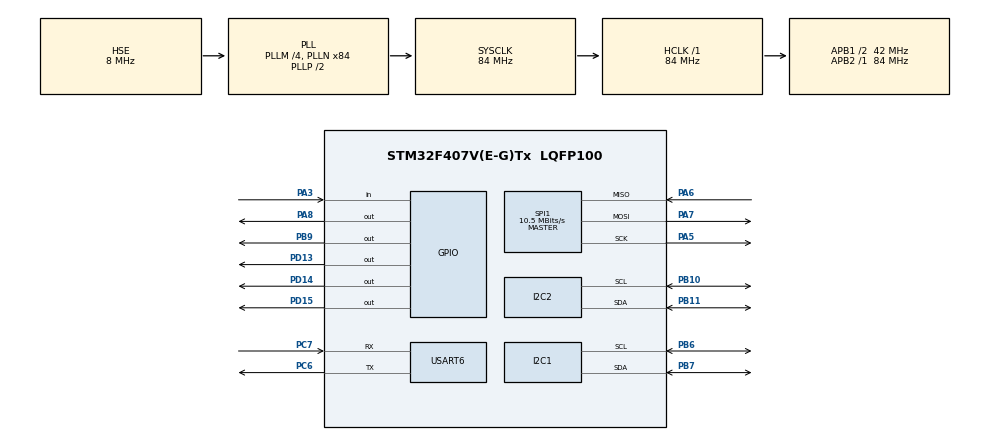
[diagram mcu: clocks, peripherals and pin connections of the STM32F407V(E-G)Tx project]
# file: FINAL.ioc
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Mcu.Family=STM32F4
Mcu.Name=STM32F407V(E-G)Tx
Mcu.Package=LQFP100
NVIC.PriorityGroup=NVIC_PRIORITYGROUP_0
PA13.Mode=Serial_Wire
PA13.Signal=SYS_JTMS-SWDIO
PA14.Mode=Serial_Wire
PA14.Signal=SYS_JTCK-SWCLK
PA3.Signal=GPIO_Input
PA5.Mode=Full_Duplex_Master
PA5.Signal=SPI1_SCK
PA6.Mode=Full_Duplex_Master
PA6.Signal=SPI1_MISO
PA7.Mode=Full_Duplex_Master
PA7.Signal=SPI1_MOSI
PA8.Signal=GPIO_Output
PB10.Mode=I2C
PB10.Signal=I2C2_SCL
PB11.Mode=I2C
PB11.Signal=I2C2_SDA
PB6.Mode=I2C
PB6.Signal=I2C1_SCL
PB7.Mode=I2C
PB7.Signal=I2C1_SDA
PB9.Signal=GPIO_Output
PC6.Mode=Asynchronous
PC6.Signal=USART6_TX
PC7.Mode=Asynchronous
PC7.Signal=USART6_RX
PD13.Signal=GPIO_Output
PD14.Signal=GPIO_Output
PD15.Signal=GPIO_Output
PH0-OSC_IN.Mode=HSE-External-Oscillator
PH0-OSC_IN.Signal=RCC_OSC_IN
PH1-OSC_OUT.Mode=HSE-External-Oscillator
PH1-OSC_OUT.Signal=RCC_OSC_OUT
ProjectManager.HeapSize=0x200
ProjectManager.StackSize=0x400
ProjectManager.TargetToolchain=MDK-ARM V5.32
RCC.48MHZClocksFreq_Value=24000000
RCC.AHBFreq_Value=84000000
RCC.APB1CLKDivider=RCC_HCLK_DIV2
RCC.APB1Freq_Value=42000000
RCC.APB1TimFreq_Value=84000000
RCC.APB2Freq_Value=84000000
RCC.APB2TimFreq_Value=84000000
RCC.CortexFreq_Value=84000000
RCC.HCLKFreq_Value=84000000
RCC.HSE_VALUE=8000000
RCC.HSI_VALUE=16000000
RCC.LSE_VALUE=32768
RCC.PLLM=4
RCC.PLLN=84
RCC.PLLQ=7
RCC.PLLSourceVirtual=RCC_PLLSOURCE_HSE
RCC.SYSCLKFreq_VALUE=84000000
RCC.SYSCLKSource=RCC_SYSCLKSOURCE_PLLCLK
RCC.VCOOutputFreq_Value=168000000
SPI1.BaudRatePrescaler=SPI_BAUDRATEPRESCALER_8
SPI1.CalculateBaudRate=10.5 MBits/s
SPI1.Direction=SPI_DIRECTION_2LINES
SPI1.Mode=SPI_MODE_MASTER
SPI1.VirtualType=VM_MASTER
USART6.VirtualMode=VM_ASYNC
board=STM32F407G-DISC1

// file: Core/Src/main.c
/* USER CODE BEGIN Header */
/**
  ******************************************************************************
  * @file           : main.c
  * @brief          : Main program body
  ******************************************************************************
  * @attention
  *
  * Copyright (c) 2025 STMicroelectronics.
  * All rights reserved.
  *
  * This software is licensed under terms that can be found in the LICENSE file
  * in the root directory of this software component.
  * If no LICENSE file comes with this software, it is provided AS-IS.
  *
  ******************************************************************************
  */
/* USER CODE END Header */
#include "main.h"
#include "RC522.h"
#include "string.h"
#include "TJ_MPU6050.h"
#include "liquidcrystal_i2c.h"
uint8_t i;
#define HIGH_BYTE(x) ((x >> 12) & 0xFF)

I2C_HandleTypeDef hi2c1;
I2C_HandleTypeDef hi2c2;

SPI_HandleTypeDef hspi1;

UART_HandleTypeDef huart6;

void SystemClock_Config(void);
static void MX_GPIO_Init(void);
static void MX_I2C1_Init(void);
static void MX_I2C2_Init(void);
static void MX_SPI1_Init(void);
static void MX_USART6_UART_Init(void);
uint8_t status;
uint8_t str[16];
uint8_t sNum[5];
RawData_Def rawaccelo, rawgyro;
ScaledData_Def scaledaccelo, scaledgyro;
ScaledData_Def previacc,previgyro;
RawData_Def prevacc,prevgyro;

int main(void)
	{
MPU_ConfigTypeDef myconfig;

  /* MCU Configuration--------------------------------------------------------*/

  /* Reset of all peripherals, Initializes the Flash interface and the Systick. */
  HAL_Init();

  /* Configure the system clock */
  SystemClock_Config();

  /* Initialize all configured peripherals */
  MX_GPIO_Init();
  MX_I2C1_Init();
  MX_I2C2_Init();
  MX_SPI1_Init();
  MX_USART6_UART_Init();
	MFRC522_Init();
	MPU6050_Init(&hi2c2);
	myconfig.Accel_Full_Scale=AFS_SEL_4g;
	myconfig.ClockSource=Internal_8MHz;
	myconfig.CONFIG_DLPF=DLPF_184A_188G_Hz;
	myconfig.Gyro_Full_Scale=FS_SEL_500;
	myconfig.Sleep_Mode_Bit=0;
	MPU6050_Config(&myconfig);
	HD44780_Backlight();
 HD44780_Init(2);
  HD44780_Clear();
	previacc = (ScaledData_Def){0};
	prevacc = (RawData_Def){0};
uint8_t tag_found = 0;

  /* Infinite loop */
  /* USER CODE BEGIN WHILE */
  while (1)
  {HD44780_Clear();
    /* USER CODE END WHILE */
		MPU6050_Get_Accel_RawData(&rawaccelo);
		MPU6050_Get_Accel_Scale(&scaledaccelo);

		if (HIGH_BYTE(rawaccelo.x) != HIGH_BYTE(prevacc.x) ||
    HIGH_BYTE(rawaccelo.y) != HIGH_BYTE(prevacc.y) ||
    HIGH_BYTE(rawaccelo.z) != HIGH_BYTE(prevacc.z)) {
    // Movement detected
		HAL_GPIO_WritePin(GPIOD,GPIO_PIN_14,GPIO_PIN_SET);
		HAL_UART_Transmit(&huart6, (uint8_t*)"The thing is moved", strlen("The thing is moved "), 1000);
		HAL_Delay(100);
		HD44780_SetCursor(0,1);
			HD44780_PrintStr("Danger");
		HAL_Delay(1000);

}

		else
		{
			HD44780_SetCursor(0, 1);
HD44780_PrintStr("                ");
			HAL_GPIO_WritePin(GPIOD,GPIO_PIN_14,GPIO_PIN_RESET);

		}
		prevacc=rawaccelo;

		if(HAL_GPIO_ReadPin(GPIOA,GPIO_PIN_3)==GPIO_PIN_RESET){
			HAL_GPIO_WritePin(GPIOD,GPIO_PIN_13,GPIO_PIN_SET);
			HAL_UART_Transmit(&huart6, (uint8_t*)"Entry detected", strlen("Entry detected"), 1000);
			HAL_Delay(100);
			HD44780_Clear();
			HD44780_SetCursor(0,0);
			 HD44780_PrintStr("Entry Detected");
			HD44780_SetCursor(0,1);
			HD44780_PrintStr("Scan Card");
			 HD44780_Display();
			HAL_Delay(1000);
			tag_found = 0;
memset(sNum, 0, sizeof(sNum));
			i=0;
			while(i<25){
		status=MFRC522_Request(PICC_REQIDL,str);
		status=MFRC522_Anticoll(str);

		HAL_Delay(200);
				i++;
				if (status == MI_OK) {
            memcpy(sNum, str, 5);
            tag_found = 1;
            break;  // Exit early on success
        }
			}
			if(sNum[2]==0x20){
				HD44780_Clear();
				HD44780_SetCursor(0,0);
				HD44780_PrintStr("Authorized");
				 HD44780_Display();
				HAL_Delay(100);
				HAL_UART_Transmit(&huart6, (uint8_t*)"Authorizedaccess", strlen("Authorizedaccess"), 1000);
				HAL_Delay(3000);
				sNum[2]=0x00;
			}
			else if(sNum[2]==0xC8){
				HAL_UART_Transmit(&huart6, (uint8_t*)"Unauthorized access", strlen("Unauthorized access"), 1000);
				HAL_GPIO_WritePin(GPIOD,GPIO_PIN_15,GPIO_PIN_SET);
				HAL_Delay(100);
				HD44780_Clear();
				HD44780_SetCursor(0,0);
				HD44780_PrintStr("unauthorized");
			 HD44780_Display();
				HAL_Delay(3000);
				sNum[2]=0x00;
				HAL_GPIO_WritePin(GPIOD,GPIO_PIN_15,GPIO_PIN_RESET);
			}
			else if(sNum[2]==0x25){
				HD44780_Clear();
				HD44780_SetCursor(0,0);
				HD44780_PrintStr("Authorized");
				HD44780_Display();
				HAL_Delay(100);
				HAL_UART_Transmit(&huart6, (uint8_t*)"Authorizedaccess", strlen("Authorizedaccess"), 1000);
				HAL_Delay(3000);
				sNum[2]=0x00;
			}

			else{
				HAL_GPIO_WritePin(GPIOD,GPIO_PIN_15,GPIO_PIN_SET);
				HD44780_Clear();
				HD44780_SetCursor(0,0);
				HD44780_PrintStr("No scan");
				HD44780_Display();
				HAL_Delay(100);
				HAL_UART_Transmit(&huart6, (uint8_t*)"No scan detected", strlen("No scan detected"), 1000);
				HAL_Delay(3000);
				HAL_GPIO_WritePin(GPIOD,GPIO_PIN_15,GPIO_PIN_RESET);
			}

}
else {
HAL_GPIO_WritePin(GPIOD,GPIO_PIN_13,GPIO_PIN_RESET);
	HAL_Delay(1000);
}

  }
}

void SystemClock_Config(void)
{
  RCC_OscInitTypeDef RCC_OscInitStruct = {0};
  RCC_ClkInitTypeDef RCC_ClkInitStruct = {0};

  /** Configure the main internal regulator output voltage
  */
  __HAL_RCC_PWR_CLK_ENABLE();
  __HAL_PWR_VOLTAGESCALING_CONFIG(PWR_REGULATOR_VOLTAGE_SCALE1);

  /** Initializes the RCC Oscillators according to the specified parameters
  * in the RCC_OscInitTypeDef structure.
  */
  RCC_OscInitStruct.OscillatorType = RCC_OSCILLATORTYPE_HSE;
  RCC_OscInitStruct.HSEState = RCC_HSE_ON;
  RCC_OscInitStruct.PLL.PLLState = RCC_PLL_ON;
  RCC_OscInitStruct.PLL.PLLSource = RCC_PLLSOURCE_HSE;
  RCC_OscInitStruct.PLL.PLLM = 4;
  RCC_OscInitStruct.PLL.PLLN = 84;
  RCC_OscInitStruct.PLL.PLLP = RCC_PLLP_DIV2;
  RCC_OscInitStruct.PLL.PLLQ = 7;
  if (HAL_RCC_OscConfig(&RCC_OscInitStruct) != HAL_OK)
  {
    Error_Handler();
  }

  /** Initializes the CPU, AHB and APB buses clocks
  */
  RCC_ClkInitStruct.ClockType = RCC_CLOCKTYPE_HCLK|RCC_CLOCKTYPE_SYSCLK
                              |RCC_CLOCKTYPE_PCLK1|RCC_CLOCKTYPE_PCLK2;
  RCC_ClkInitStruct.SYSCLKSource = RCC_SYSCLKSOURCE_PLLCLK;
  RCC_ClkInitStruct.AHBCLKDivider = RCC_SYSCLK_DIV1;
  RCC_ClkInitStruct.APB1CLKDivider = RCC_HCLK_DIV2;
  RCC_ClkInitStruct.APB2CLKDivider = RCC_HCLK_DIV1;

  if (HAL_RCC_ClockConfig(&RCC_ClkInitStruct, FLASH_LATENCY_2) != HAL_OK)
  {
    Error_Handler();
  }
}

static void MX_I2C1_Init(void)
{

  hi2c1.Instance = I2C1;
  hi2c1.Init.ClockSpeed = 100000;
  hi2c1.Init.DutyCycle = I2C_DUTYCYCLE_2;
  hi2c1.Init.OwnAddress1 = 0;
  hi2c1.Init.AddressingMode = I2C_ADDRESSINGMODE_7BIT;
  hi2c1.Init.DualAddressMode = I2C_DUALADDRESS_DISABLE;
  hi2c1.Init.OwnAddress2 = 0;
  hi2c1.Init.GeneralCallMode = I2C_GENERALCALL_DISABLE;
  hi2c1.Init.NoStretchMode = I2C_NOSTRETCH_DISABLE;
  if (HAL_I2C_Init(&hi2c1) != HAL_OK)
  {
    Error_Handler();
  }

}

static void MX_I2C2_Init(void)
{

  hi2c2.Instance = I2C2;
  hi2c2.Init.ClockSpeed = 100000;
  hi2c2.Init.DutyCycle = I2C_DUTYCYCLE_2;
  hi2c2.Init.OwnAddress1 = 0;
  hi2c2.Init.AddressingMode = I2C_ADDRESSINGMODE_7BIT;
  hi2c2.Init.DualAddressMode = I2C_DUALADDRESS_DISABLE;
  hi2c2.Init.OwnAddress2 = 0;
  hi2c2.Init.GeneralCallMode = I2C_GENERALCALL_DISABLE;
  hi2c2.Init.NoStretchMode = I2C_NOSTRETCH_DISABLE;
  if (HAL_I2C_Init(&hi2c2) != HAL_OK)
  {
    Error_Handler();
  }

}

static void MX_SPI1_Init(void)
{

  /* SPI1 parameter configuration*/
  hspi1.Instance = SPI1;
  hspi1.Init.Mode = SPI_MODE_MASTER;
  hspi1.Init.Direction = SPI_DIRECTION_2LINES;
  hspi1.Init.DataSize = SPI_DATASIZE_8BIT;
  hspi1.Init.CLKPolarity = SPI_POLARITY_LOW;
  hspi1.Init.CLKPhase = SPI_PHASE_1EDGE;
  hspi1.Init.NSS = SPI_NSS_SOFT;
  hspi1.Init.BaudRatePrescaler = SPI_BAUDRATEPRESCALER_8;
  hspi1.Init.FirstBit = SPI_FIRSTBIT_MSB;
  hspi1.Init.TIMode = SPI_TIMODE_DISABLE;
  hspi1.Init.CRCCalculation = SPI_CRCCALCULATION_DISABLE;
  hspi1.Init.CRCPolynomial = 10;
  if (HAL_SPI_Init(&hspi1) != HAL_OK)
  {
    Error_Handler();
  }

}

static void MX_USART6_UART_Init(void)
{

  huart6.Instance = USART6;
  huart6.Init.BaudRate = 115200;
  huart6.Init.WordLength = UART_WORDLENGTH_8B;
  huart6.Init.StopBits = UART_STOPBITS_1;
  huart6.Init.Parity = UART_PARITY_NONE;
  huart6.Init.Mode = UART_MODE_TX_RX;
  huart6.Init.HwFlowCtl = UART_HWCONTROL_NONE;
  huart6.Init.OverSampling = UART_OVERSAMPLING_16;
  if (HAL_UART_Init(&huart6) != HAL_OK)
  {
    Error_Handler();
  }

}

static void MX_GPIO_Init(void)
{
  GPIO_InitTypeDef GPIO_InitStruct = {0};

  /* GPIO Ports Clock Enable */
  __HAL_RCC_GPIOH_CLK_ENABLE();
  __HAL_RCC_GPIOA_CLK_ENABLE();
  __HAL_RCC_GPIOB_CLK_ENABLE();
  __HAL_RCC_GPIOD_CLK_ENABLE();
  __HAL_RCC_GPIOC_CLK_ENABLE();

  /*Configure GPIO pin Output Level */
  HAL_GPIO_WritePin(GPIOD, GPIO_PIN_13|GPIO_PIN_14|GPIO_PIN_15, GPIO_PIN_RESET);

  /*Configure GPIO pin Output Level */
  HAL_GPIO_WritePin(GPIOA, GPIO_PIN_8, GPIO_PIN_RESET);

  /*Configure GPIO pin Output Level */
  HAL_GPIO_WritePin(GPIOB, GPIO_PIN_9, GPIO_PIN_RESET);

  /*Configure GPIO pin : PA3 */
  GPIO_InitStruct.Pin = GPIO_PIN_3;
  GPIO_InitStruct.Mode = GPIO_MODE_INPUT;
  GPIO_InitStruct.Pull = GPIO_NOPULL;
  HAL_GPIO_Init(GPIOA, &GPIO_InitStruct);

  /*Configure GPIO pins : PD13 PD14 PD15 */
  GPIO_InitStruct.Pin = GPIO_PIN_13|GPIO_PIN_14|GPIO_PIN_15;
  GPIO_InitStruct.Mode = GPIO_MODE_OUTPUT_PP;
  GPIO_InitStruct.Pull = GPIO_NOPULL;
  GPIO_InitStruct.Speed = GPIO_SPEED_FREQ_LOW;
  HAL_GPIO_Init(GPIOD, &GPIO_InitStruct);

  /*Configure GPIO pin : PA8 */
  GPIO_InitStruct.Pin = GPIO_PIN_8;
  GPIO_InitStruct.Mode = GPIO_MODE_OUTPUT_PP;
  GPIO_InitStruct.Pull = GPIO_NOPULL;
  GPIO_InitStruct.Speed = GPIO_SPEED_FREQ_LOW;
  HAL_GPIO_Init(GPIOA, &GPIO_InitStruct);

  /*Configure GPIO pin : PB9 */
  GPIO_InitStruct.Pin = GPIO_PIN_9;
  GPIO_InitStruct.Mode = GPIO_MODE_OUTPUT_PP;
  GPIO_InitStruct.Pull = GPIO_NOPULL;
  GPIO_InitStruct.Speed = GPIO_SPEED_FREQ_LOW;
  HAL_GPIO_Init(GPIOB, &GPIO_InitStruct);

}

void Error_Handler(void)
{
  __disable_irq();
  while (1)
  {
  }
}
